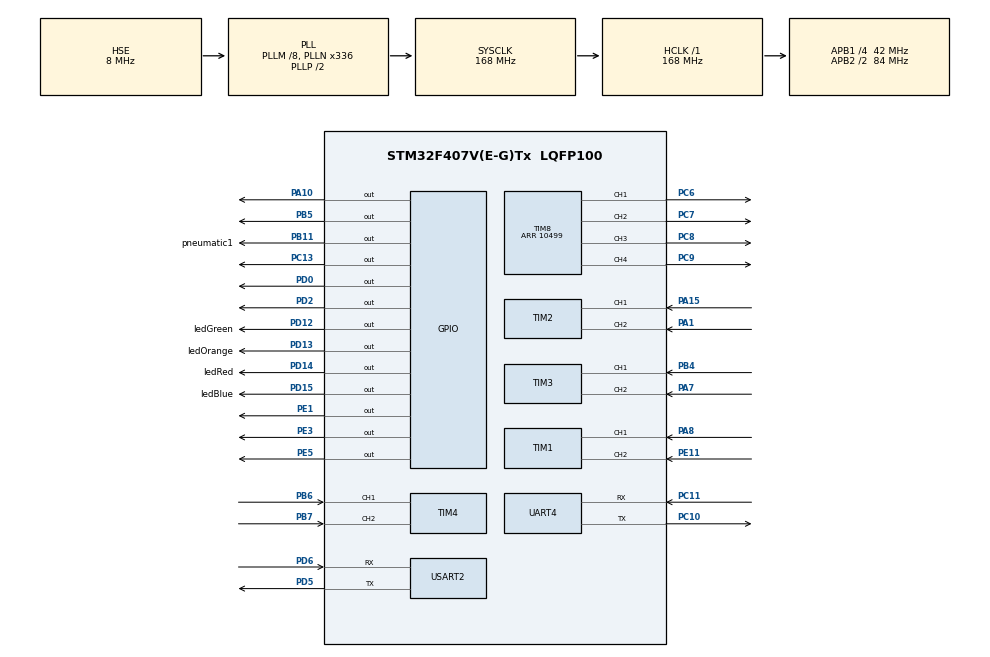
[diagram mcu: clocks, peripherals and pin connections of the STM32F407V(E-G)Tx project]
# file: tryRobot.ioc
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Dma.Request0=USART2_RX
Dma.Request1=UART4_TX
Dma.UART4_TX.1.Direction=DMA_MEMORY_TO_PERIPH
Dma.UART4_TX.1.FIFOMode=DMA_FIFOMODE_DISABLE
Dma.UART4_TX.1.Instance=DMA1_Stream4
Dma.UART4_TX.1.MemDataAlignment=DMA_MDATAALIGN_BYTE
Dma.UART4_TX.1.MemInc=DMA_MINC_ENABLE
Dma.UART4_TX.1.Mode=DMA_NORMAL
Dma.UART4_TX.1.PeriphDataAlignment=DMA_PDATAALIGN_BYTE
Dma.UART4_TX.1.PeriphInc=DMA_PINC_DISABLE
Dma.UART4_TX.1.Priority=DMA_PRIORITY_LOW
Dma.USART2_RX.0.Direction=DMA_PERIPH_TO_MEMORY
Dma.USART2_RX.0.FIFOMode=DMA_FIFOMODE_DISABLE
Dma.USART2_RX.0.Instance=DMA1_Stream5
Dma.USART2_RX.0.MemDataAlignment=DMA_MDATAALIGN_BYTE
Dma.USART2_RX.0.MemInc=DMA_MINC_ENABLE
Dma.USART2_RX.0.Mode=DMA_CIRCULAR
Dma.USART2_RX.0.PeriphDataAlignment=DMA_PDATAALIGN_BYTE
Dma.USART2_RX.0.PeriphInc=DMA_PINC_DISABLE
Dma.USART2_RX.0.Priority=DMA_PRIORITY_LOW
Mcu.Family=STM32F4
Mcu.Name=STM32F407V(E-G)Tx
Mcu.Package=LQFP100
NVIC.DMA1_Stream4_IRQn=true\:0\:0\:false\:false\:true\:false\:true
NVIC.DMA1_Stream5_IRQn=true\:0\:0\:false\:false\:true\:false\:true
NVIC.PriorityGroup=NVIC_PRIORITYGROUP_0
NVIC.TIM1_BRK_TIM9_IRQn=true\:0\:0\:false\:false\:true\:true\:true
NVIC.TIM1_CC_IRQn=true\:0\:0\:false\:false\:true\:true\:true
NVIC.TIM1_TRG_COM_TIM11_IRQn=true\:0\:0\:false\:false\:true\:true\:true
NVIC.TIM1_UP_TIM10_IRQn=true\:0\:0\:false\:false\:true\:true\:true
NVIC.TIM2_IRQn=true\:0\:0\:false\:false\:true\:true\:true
NVIC.TIM3_IRQn=true\:0\:0\:false\:false\:true\:true\:true
NVIC.TIM4_IRQn=true\:0\:0\:false\:false\:true\:true\:true
NVIC.TIM8_UP_TIM13_IRQn=true\:0\:0\:false\:false\:true\:true\:true
NVIC.UART4_IRQn=true\:0\:0\:false\:false\:true\:true\:true
NVIC.USART2_IRQn=true\:0\:0\:false\:false\:true\:true\:true
PA1.GPIO_PuPd=GPIO_PULLUP
PA1.Signal=S_TIM2_CH2
PA10.Signal=GPIO_Output
PA13.Mode=Trace_Asynchronous_SW
PA13.Signal=SYS_JTMS-SWDIO
PA14.Mode=Trace_Asynchronous_SW
PA14.Signal=SYS_JTCK-SWCLK
PA15.GPIO_PuPd=GPIO_PULLUP
PA15.Signal=S_TIM2_CH1_ETR
PA7.GPIO_PuPd=GPIO_PULLUP
PA7.Signal=S_TIM3_CH2
PA8.GPIO_PuPd=GPIO_PULLUP
PA8.Signal=S_TIM1_CH1
PB11.GPIO_Label=pneumatic1
PB11.Signal=GPIO_Output
PB3.Mode=Trace_Asynchronous_SW
PB3.Signal=SYS_JTDO-SWO
PB4.GPIO_PuPd=GPIO_PULLUP
PB4.Signal=S_TIM3_CH1
PB5.Signal=GPIO_Output
PB6.GPIO_PuPd=GPIO_PULLUP
PB6.Signal=S_TIM4_CH1
PB7.GPIO_PuPd=GPIO_PULLUP
PB7.Signal=S_TIM4_CH2
PC10.Mode=Asynchronous
PC10.Signal=UART4_TX
PC11.Mode=Asynchronous
PC11.Signal=UART4_RX
PC13-ANTI_TAMP.Signal=GPIO_Output
PC6.Signal=S_TIM8_CH1
PC7.Signal=S_TIM8_CH2
PC8.Signal=S_TIM8_CH3
PC9.Signal=S_TIM8_CH4
PD0.Signal=GPIO_Output
PD12.GPIO_Label=ledGreen
PD12.Signal=GPIO_Output
PD13.GPIO_Label=ledOrange
PD13.Signal=GPIO_Output
PD14.GPIO_Label=ledRed
PD14.Signal=GPIO_Output
PD15.GPIO_Label=ledBlue
PD15.Signal=GPIO_Output
PD2.Signal=GPIO_Output
PD5.Mode=Asynchronous
PD5.Signal=USART2_TX
PD6.Mode=Asynchronous
PD6.Signal=USART2_RX
PE1.Signal=GPIO_Output
PE11.GPIO_PuPd=GPIO_PULLUP
PE11.Signal=S_TIM1_CH2
PE3.Signal=GPIO_Output
PE5.Signal=GPIO_Output
PH0-OSC_IN.Mode=HSE-External-Oscillator
PH0-OSC_IN.Signal=RCC_OSC_IN
PH1-OSC_OUT.Mode=HSE-External-Oscillator
PH1-OSC_OUT.Signal=RCC_OSC_OUT
ProjectManager.HeapSize=0x200
ProjectManager.StackSize=0x400
ProjectManager.TargetToolchain=Makefile
RCC.48MHZClocksFreq_Value=48000000
RCC.AHBFreq_Value=168000000
RCC.APB1CLKDivider=RCC_HCLK_DIV4
RCC.APB1Freq_Value=42000000
RCC.APB1TimFreq_Value=84000000
RCC.APB2CLKDivider=RCC_HCLK_DIV2
RCC.APB2Freq_Value=84000000
RCC.APB2TimFreq_Value=168000000
RCC.CortexFreq_Value=168000000
RCC.HCLKFreq_Value=168000000
RCC.HSE_VALUE=8000000
RCC.HSI_VALUE=16000000
RCC.LSE_VALUE=32768
RCC.PLLM=8
RCC.PLLN=336
RCC.PLLQ=7
RCC.PLLSourceVirtual=RCC_PLLSOURCE_HSE
RCC.SYSCLKFreq_VALUE=168000000
RCC.SYSCLKSource=RCC_SYSCLKSOURCE_PLLCLK
RCC.VCOOutputFreq_Value=336000000
SH.S_TIM1_CH1.0=TIM1_CH1,Encoder_Interface
SH.S_TIM1_CH2.0=TIM1_CH2,Encoder_Interface
SH.S_TIM2_CH1_ETR.0=TIM2_CH1,Encoder_Interface
SH.S_TIM2_CH2.0=TIM2_CH2,Encoder_Interface
SH.S_TIM3_CH1.0=TIM3_CH1,Encoder_Interface
SH.S_TIM3_CH2.0=TIM3_CH2,Encoder_Interface
SH.S_TIM4_CH1.0=TIM4_CH1,Encoder_Interface
SH.S_TIM4_CH2.0=TIM4_CH2,Encoder_Interface
SH.S_TIM8_CH1.0=TIM8_CH1,PWM Generation1 CH1
SH.S_TIM8_CH2.0=TIM8_CH2,PWM Generation2 CH2
SH.S_TIM8_CH3.0=TIM8_CH3,PWM Generation3 CH3
SH.S_TIM8_CH4.0=TIM8_CH4,PWM Generation4 CH4
TIM1.EncoderMode=TIM_ENCODERMODE_TI12
TIM2.EncoderMode=TIM_ENCODERMODE_TI12
TIM3.EncoderMode=TIM_ENCODERMODE_TI12
TIM4.EncoderMode=TIM_ENCODERMODE_TI12
TIM8.Channel-PWM\ Generation1\ CH1=TIM_CHANNEL_1
TIM8.Channel-PWM\ Generation2\ CH2=TIM_CHANNEL_2
TIM8.Channel-PWM\ Generation3\ CH3=TIM_CHANNEL_3
TIM8.Channel-PWM\ Generation4\ CH4=TIM_CHANNEL_4
TIM8.CounterMode=TIM_COUNTERMODE_CENTERALIGNED1
TIM8.Period=10499
UART4.VirtualMode=Asynchronous
USART2.VirtualMode=VM_ASYNC
board=STM32F4DISCOVERY

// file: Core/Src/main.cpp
/* USER CODE BEGIN Header */
/**
  ******************************************************************************
  * @file           : main.c
  * @brief          : Main program body
  ******************************************************************************
  * @attention
  *
  * <h2><center>&copy; Copyright (c) 2019 STMicroelectronics.
  * All rights reserved.</center></h2>
  *
  * This software component is licensed by ST under BSD 3-Clause license,
  * the "License"; You may not use this file except in compliance with the
  * License. You may obtain a copy of the License at:
  *                        opensource.org/licenses/BSD-3-Clause
  *
  ******************************************************************************
  */
/* USER CODE END Header */

#include "main.h"
#include "dma.h"
#include "tim.h"
#include "usart.h"
#include "gpio.h"
/* USER CODE BEGIN Includes */
#include "robo_init.h"
#include "motor.h"
#include "actuator.h"
/* USER CODE END Includes */

void SystemClock_Config(void);

int main(void)
{

  /* MCU Configuration--------------------------------------------------------*/

  /* Reset of all peripherals, Initializes the Flash interface and the Systick. */
  HAL_Init();

  /* Configure the system clock */
  SystemClock_Config();

  /* Initialize all configured peripherals */
  MX_GPIO_Init();
  MX_DMA_Init();
  MX_TIM1_Init();
  MX_TIM2_Init();
  MX_TIM3_Init();
  MX_TIM4_Init();
  MX_TIM8_Init();
  MX_UART4_Init();
  MX_USART2_UART_Init();

  /* USER CODE BEGIN 2 */
  robo_init();
  /* USER CODE END 2 */
  /* Infinite loop */
  while (1)
  {

    /* USER CODE BEGIN 3 */
    play();
  }
  /* USER CODE END 3 */
}

void SystemClock_Config(void)
{
  RCC_OscInitTypeDef RCC_OscInitStruct = {0};
  RCC_ClkInitTypeDef RCC_ClkInitStruct = {0};

  /** Configure the main internal regulator output voltage
  */
  __HAL_RCC_PWR_CLK_ENABLE();
  __HAL_PWR_VOLTAGESCALING_CONFIG(PWR_REGULATOR_VOLTAGE_SCALE1);
  /** Initializes the CPU, AHB and APB busses clocks
  */
  RCC_OscInitStruct.OscillatorType = RCC_OSCILLATORTYPE_HSE;
  RCC_OscInitStruct.HSEState = RCC_HSE_ON;
  RCC_OscInitStruct.PLL.PLLState = RCC_PLL_ON;
  RCC_OscInitStruct.PLL.PLLSource = RCC_PLLSOURCE_HSE;
  RCC_OscInitStruct.PLL.PLLM = 8;
  RCC_OscInitStruct.PLL.PLLN = 336;
  RCC_OscInitStruct.PLL.PLLP = RCC_PLLP_DIV2;
  RCC_OscInitStruct.PLL.PLLQ = 7;
  if (HAL_RCC_OscConfig(&RCC_OscInitStruct) != HAL_OK)
  {
    Error_Handler();
  }
  /** Initializes the CPU, AHB and APB busses clocks
  */
  RCC_ClkInitStruct.ClockType = RCC_CLOCKTYPE_HCLK | RCC_CLOCKTYPE_SYSCLK | RCC_CLOCKTYPE_PCLK1 | RCC_CLOCKTYPE_PCLK2;
  RCC_ClkInitStruct.SYSCLKSource = RCC_SYSCLKSOURCE_PLLCLK;
  RCC_ClkInitStruct.AHBCLKDivider = RCC_SYSCLK_DIV1;
  RCC_ClkInitStruct.APB1CLKDivider = RCC_HCLK_DIV4;
  RCC_ClkInitStruct.APB2CLKDivider = RCC_HCLK_DIV2;

  if (HAL_RCC_ClockConfig(&RCC_ClkInitStruct, FLASH_LATENCY_5) != HAL_OK)
  {
    Error_Handler();
  }
}

void Error_Handler(void)
{
}

/************************ (C) COPYRIGHT STMicroelectronics *****END OF FILE****/
